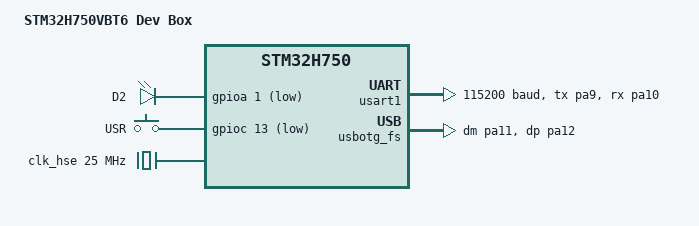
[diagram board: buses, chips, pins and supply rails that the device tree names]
/*
 * SPDX-License-Identifier: Apache-2.0
 */

/dts-v1/;
#include <st/h7/stm32h750Xb.dtsi>
#include <st/h7/stm32h750vbtx-pinctrl.dtsi>
#include <zephyr/dt-bindings/input/input-event-codes.h>

/ {
	model = "STM32H750VBT6 Dev Box";
	compatible = "custom,stm32h750_devbox";

	aliases {
		led0 = &led_1;
		sw0 = &user_button;
	};

	chosen {
		zephyr,console = &cdc_acm_uart0;
		zephyr,shell-uart = &cdc_acm_uart0;
		zephyr,sram = &sram0;
		zephyr,flash = &flash0;
	};

	leds {
		compatible = "gpio-leds";

		led_1: led_1 {
			/* D2 LED on PA1, sink mode (active-low) */
			gpios = <&gpioa 1 GPIO_ACTIVE_LOW>;
			label = "D2";
		};
	};

	gpio_keys {
		compatible = "gpio-keys";

		user_button: button {
			gpios = <&gpioc 13 (GPIO_ACTIVE_LOW | GPIO_PULL_UP)>;
			zephyr,code = <INPUT_KEY_0>;
			label = "USR";
		};
	};
};

&clk_hse {
	clock-frequency = <DT_FREQ_M(25)>;
	status = "okay";
};

&clk_lse {
	status = "okay";
};

&clk_hsi48 {
	status = "okay";
};

&pll {
	div-m = <5>;
	mul-n = <192>;
	div-p = <2>;
	div-q = <4>;
	div-r = <4>;
	clocks = <&clk_hse>;
	status = "okay";
};

&rcc {
	clocks = <&pll>;
	clock-frequency = <DT_FREQ_M(480)>;
	d1cpre = <1>;
	hpre = <2>;
	d1ppre = <2>;
	d2ppre1 = <2>;
	d2ppre2 = <2>;
	d3ppre = <2>;
};

&pwr {
	power-supply = "ldo";
};

&usart1 {
	pinctrl-names = "default";
	pinctrl-0 = <&usart1_tx_pa9 &usart1_rx_pa10>;
	current-speed = <115200>;
	status = "okay";
};

zephyr_udc0: &usbotg_fs {
	pinctrl-0 = <&usb_otg_fs_dm_pa11 &usb_otg_fs_dp_pa12>;
	pinctrl-names = "default";
	status = "okay";

	cdc_acm_uart0: cdc_acm_uart0 {
		compatible = "zephyr,cdc-acm-uart";
	};
};
